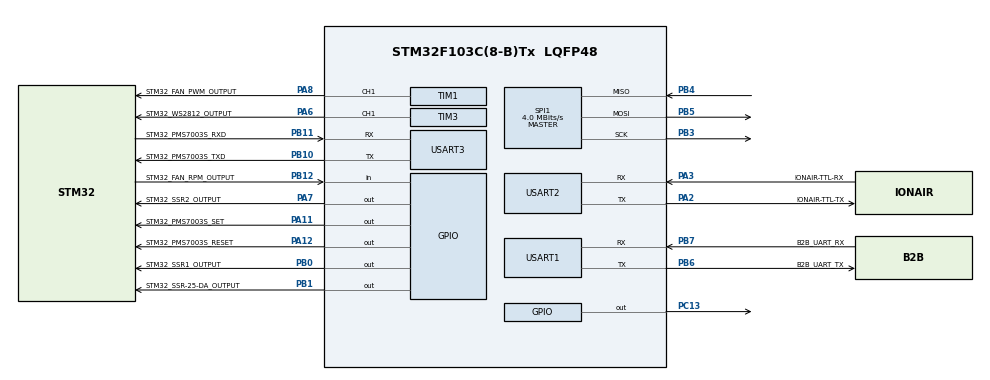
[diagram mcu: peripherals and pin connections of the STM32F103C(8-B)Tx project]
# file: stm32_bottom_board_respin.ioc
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Mcu.Family=STM32F1
Mcu.Name=STM32F103C(8-B)Tx
Mcu.Package=LQFP48
NVIC.PriorityGroup=NVIC_PRIORITYGROUP_4
PA11.GPIO_Label=STM32_PMS7003S_SET
PA11.Signal=GPIO_Output
PA12.GPIO_Label=STM32_PMS7003S_RESET
PA12.Signal=GPIO_Output
PA13.Mode=Serial_Wire
PA13.Signal=SYS_JTMS-SWDIO
PA14.Mode=Serial_Wire
PA14.Signal=SYS_JTCK-SWCLK
PA2.GPIO_Label=IONAIR-TTL-TX
PA2.Mode=Asynchronous
PA2.Signal=USART2_TX
PA3.GPIO_Label=IONAIR-TTL-RX
PA3.Mode=Asynchronous
PA3.Signal=USART2_RX
PA6.GPIO_Label=STM32_WS2812_OUTPUT
PA6.Signal=S_TIM3_CH1
PA7.GPIO_Label=STM32_SSR2_OUTPUT
PA7.Signal=GPIO_Output
PA8.GPIO_Label=STM32_FAN_PWM_OUTPUT
PA8.Signal=S_TIM1_CH1
PB0.GPIO_Label=STM32_SSR1_OUTPUT
PB0.Signal=GPIO_Output
PB1.GPIO_Label=STM32_SSR-25-DA_OUTPUT
PB1.Signal=GPIO_Output
PB10.GPIO_Label=STM32_PMS7003S_TXD
PB10.Mode=Asynchronous
PB10.Signal=USART3_TX
PB11.GPIO_Label=STM32_PMS7003S_RXD
PB11.Mode=Asynchronous
PB11.Signal=USART3_RX
PB12.GPIO_Label=STM32_FAN_RPM_OUTPUT
PB12.Signal=GPIO_Input
PB3.Mode=Full_Duplex_Master
PB3.Signal=SPI1_SCK
PB4.Mode=Full_Duplex_Master
PB4.Signal=SPI1_MISO
PB5.Mode=Full_Duplex_Master
PB5.Signal=SPI1_MOSI
PB6.GPIO_Label=B2B_UART_TX
PB6.Mode=Asynchronous
PB6.Signal=USART1_TX
PB7.GPIO_Label=B2B_UART_RX
PB7.Mode=Asynchronous
PB7.Signal=USART1_RX
PC13-TAMPER-RTC.Signal=GPIO_Output
ProjectManager.HeapSize=0x200
ProjectManager.StackSize=0x400
ProjectManager.TargetToolchain=Makefile
RCC.APB1Freq_Value=8000000
RCC.APB2Freq_Value=8000000
SH.S_TIM1_CH1.0=TIM1_CH1,PWM Generation1 CH1
SH.S_TIM3_CH1.0=TIM3_CH1,PWM Generation1 CH1
SPI1.CalculateBaudRate=4.0 MBits/s
SPI1.Direction=SPI_DIRECTION_2LINES
SPI1.Mode=SPI_MODE_MASTER
SPI1.VirtualType=VM_MASTER
TIM1.Channel-PWM\ Generation1\ CH1=TIM_CHANNEL_1
TIM3.Channel-PWM\ Generation1\ CH1=TIM_CHANNEL_1
USART1.VirtualMode=VM_ASYNC
USART2.VirtualMode=VM_ASYNC
USART3.VirtualMode=VM_ASYNC
board=custom

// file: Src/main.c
/**
  ******************************************************************************
  * @file           : main.c
  * @brief          : Main program body
  ******************************************************************************
  ** This notice applies to any and all portions of this file
  * that are not between comment pairs USER CODE BEGIN and
  * USER CODE END. Other portions of this file, whether
  * inserted by the user or by software development tools
  * are owned by their respective copyright owners.
  *
  * COPYRIGHT(c) 2018 STMicroelectronics
  *
  * Redistribution and use in source and binary forms, with or without modification,
  * are permitted provided that the following conditions are met:
  *   1. Redistributions of source code must retain the above copyright notice,
  *      this list of conditions and the following disclaimer.
  *   2. Redistributions in binary form must reproduce the above copyright notice,
  *      this list of conditions and the following disclaimer in the documentation
  *      and/or other materials provided with the distribution.
  *   3. Neither the name of STMicroelectronics nor the names of its contributors
  *      may be used to endorse or promote products derived from this software
  *      without specific prior written permission.
  *
  * THIS SOFTWARE IS PROVIDED BY THE COPYRIGHT HOLDERS AND CONTRIBUTORS "AS IS"
  * AND ANY EXPRESS OR IMPLIED WARRANTIES, INCLUDING, BUT NOT LIMITED TO, THE
  * IMPLIED WARRANTIES OF MERCHANTABILITY AND FITNESS FOR A PARTICULAR PURPOSE ARE
  * DISCLAIMED. IN NO EVENT SHALL THE COPYRIGHT HOLDER OR CONTRIBUTORS BE LIABLE
  * FOR ANY DIRECT, INDIRECT, INCIDENTAL, SPECIAL, EXEMPLARY, OR CONSEQUENTIAL
  * DAMAGES (INCLUDING, BUT NOT LIMITED TO, PROCUREMENT OF SUBSTITUTE GOODS OR
  * SERVICES; LOSS OF USE, DATA, OR PROFITS; OR BUSINESS INTERRUPTION) HOWEVER
  * CAUSED AND ON ANY THEORY OF LIABILITY, WHETHER IN CONTRACT, STRICT LIABILITY,
  * OR TORT (INCLUDING NEGLIGENCE OR OTHERWISE) ARISING IN ANY WAY OUT OF THE USE
  * OF THIS SOFTWARE, EVEN IF ADVISED OF THE POSSIBILITY OF SUCH DAMAGE.
  *
  ******************************************************************************
  */
#include "main.h"
#include "stm32f1xx_hal.h"
#include "spi.h"
#include "tim.h"
#include "usart.h"
#include "gpio.h"

/* USER CODE BEGIN PV */
/* Private variables ---------------------------------------------------------*/

/* USER CODE END PV */

void SystemClock_Config(void);

/* USER CODE BEGIN PFP */
/* Private function prototypes -----------------------------------------------*/

/* USER CODE END PFP */

int main(void)
{

  /* MCU Configuration----------------------------------------------------------*/

  /* Reset of all peripherals, Initializes the Flash interface and the Systick. */
  HAL_Init();

  /* Configure the system clock */
  SystemClock_Config();

  /* Initialize all configured peripherals */
  MX_GPIO_Init();
  MX_USART2_UART_Init();
  MX_TIM3_Init();
  MX_TIM1_Init();
  MX_USART1_UART_Init();
  MX_SPI1_Init();
  MX_USART3_UART_Init();

  /* Infinite loop */
  while (1)
  {

  /* USER CODE BEGIN 3 */
    HAL_GPIO_TogglePin(GPIOC, GPIO_PIN_13);
    HAL_GPIO_TogglePin(GPIOB, GPIO_PIN_1);
    HAL_Delay(1000);

  }
  /* USER CODE END 3 */

}

void SystemClock_Config(void)
{

  RCC_OscInitTypeDef RCC_OscInitStruct;
  RCC_ClkInitTypeDef RCC_ClkInitStruct;

    /**Initializes the CPU, AHB and APB busses clocks
    */
  RCC_OscInitStruct.OscillatorType = RCC_OSCILLATORTYPE_HSI;
  RCC_OscInitStruct.HSIState = RCC_HSI_ON;
  RCC_OscInitStruct.HSICalibrationValue = 16;
  RCC_OscInitStruct.PLL.PLLState = RCC_PLL_NONE;
  if (HAL_RCC_OscConfig(&RCC_OscInitStruct) != HAL_OK)
  {
    _Error_Handler(__FILE__, __LINE__);
  }

    /**Initializes the CPU, AHB and APB busses clocks
    */
  RCC_ClkInitStruct.ClockType = RCC_CLOCKTYPE_HCLK|RCC_CLOCKTYPE_SYSCLK
                              |RCC_CLOCKTYPE_PCLK1|RCC_CLOCKTYPE_PCLK2;
  RCC_ClkInitStruct.SYSCLKSource = RCC_SYSCLKSOURCE_HSI;
  RCC_ClkInitStruct.AHBCLKDivider = RCC_SYSCLK_DIV1;
  RCC_ClkInitStruct.APB1CLKDivider = RCC_HCLK_DIV1;
  RCC_ClkInitStruct.APB2CLKDivider = RCC_HCLK_DIV1;

  if (HAL_RCC_ClockConfig(&RCC_ClkInitStruct, FLASH_LATENCY_0) != HAL_OK)
  {
    _Error_Handler(__FILE__, __LINE__);
  }

    /**Configure the Systick interrupt time
    */
  HAL_SYSTICK_Config(HAL_RCC_GetHCLKFreq()/1000);

    /**Configure the Systick
    */
  HAL_SYSTICK_CLKSourceConfig(SYSTICK_CLKSOURCE_HCLK);

  /* SysTick_IRQn interrupt configuration */
  HAL_NVIC_SetPriority(SysTick_IRQn, 0, 0);
}

void _Error_Handler(char *file, int line)
{
  while(1)
  {
  }
}

/************************ (C) COPYRIGHT STMicroelectronics *****END OF FILE****/
